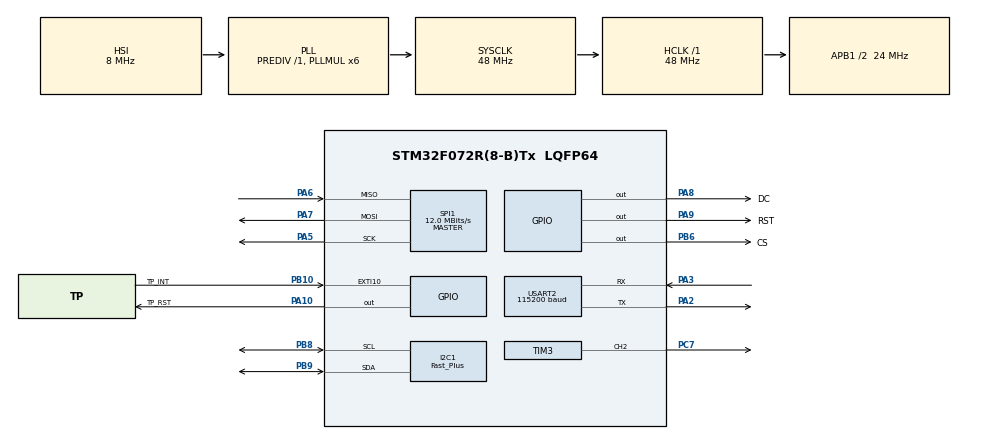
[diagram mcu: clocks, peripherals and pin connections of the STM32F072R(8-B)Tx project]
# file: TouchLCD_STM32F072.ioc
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I2C1.AddressingMode=I2C_ADDRESSINGMODE_7BIT
I2C1.DualAddressMode=I2C_DUALADDRESS_DISABLE
I2C1.GeneralCallMode=I2C_GENERALCALL_DISABLE
I2C1.I2C_Speed_Mode=I2C_Fast_Plus
I2C1.NoStretchMode=I2C_NOSTRETCH_DISABLE
I2C1.OwnAddress=0
I2C1.Timing=0x00000001
Mcu.Family=STM32F0
Mcu.Name=STM32F072R(8-B)Tx
Mcu.Package=LQFP64
NVIC.EXTI4_15_IRQn=true\:0\:0\:false\:false\:true\:true\:true\:true
PA10.GPIO_Label=TP_RST
PA10.Signal=GPIO_Output
PA13.Mode=Serial_Wire
PA13.Signal=SYS_SWDIO
PA14.Mode=Serial_Wire
PA14.Signal=SYS_SWCLK
PA2.Mode=Asynchronous
PA2.Signal=USART2_TX
PA3.Mode=Asynchronous
PA3.Signal=USART2_RX
PA5.Mode=Full_Duplex_Master
PA5.Signal=SPI1_SCK
PA6.Mode=Full_Duplex_Master
PA6.Signal=SPI1_MISO
PA7.Mode=Full_Duplex_Master
PA7.Signal=SPI1_MOSI
PA8.GPIO_Label=DC
PA8.PinState=GPIO_PIN_SET
PA8.Signal=GPIO_Output
PA9.GPIO_Label=RST
PA9.PinState=GPIO_PIN_SET
PA9.Signal=GPIO_Output
PB10.GPIO_Label=TP_INT
PB10.Signal=GPXTI10
PB6.GPIO_Label=CS
PB6.PinState=GPIO_PIN_SET
PB6.Signal=GPIO_Output
PB8.Mode=I2C
PB8.Signal=I2C1_SCL
PB9.Mode=I2C
PB9.Signal=I2C1_SDA
PC7.Signal=S_TIM3_CH2
PF0-OSC_IN.Mode=HSE-External-Oscillator
PF0-OSC_IN.Signal=RCC_OSC_IN
PF1-OSC_OUT.Mode=HSE-External-Oscillator
PF1-OSC_OUT.Signal=RCC_OSC_OUT
ProjectManager.HeapSize=0x200
ProjectManager.StackSize=0x400
ProjectManager.TargetToolchain=STM32CubeIDE
RCC.AHBFreq_Value=48000000
RCC.APB1CLKDivider=RCC_HCLK_DIV2
RCC.APB1Freq_Value=24000000
RCC.APB1TimFreq_Value=48000000
RCC.HCLKFreq_Value=48000000
RCC.PLLMUL=RCC_PLL_MUL6
RCC.PWREXT_OverDrive=PWREXT_OverDrive_ACTIVATED
RCC.PWR_Regulator_Voltage_Scale=PWR_REGULATOR_VOLTAGE_SCALE1
RCC.RCC_TIM_PRescaler_Selection=RCC_TIMPRES_DESACTIVATED
RCC.SYSCLKFreq_VALUE=48000000
RCC.SYSCLKSource=RCC_SYSCLKSOURCE_PLLCLK
SH.S_TIM3_CH2.0=TIM3_CH2,PWM Generation2 CH2
SPI1.BaudRatePrescaler=SPI_BAUDRATEPRESCALER_2
SPI1.CLKPhase=SPI_PHASE_1EDGE
SPI1.CLKPolarity=SPI_POLARITY_LOW
SPI1.CRCCalculation=SPI_CRCCALCULATION_DISABLE
SPI1.CalculateBaudRate=12.0 MBits/s
SPI1.DataSize=SPI_DATASIZE_8BIT
SPI1.Direction=SPI_DIRECTION_2LINES
SPI1.FirstBit=SPI_FIRSTBIT_MSB
SPI1.Mode=SPI_MODE_MASTER
SPI1.NSS=SPI_NSS_SOFT
SPI1.TIMode=SPI_TIMODE_DISABLE
SPI1.VirtualType=VM_MASTER
TIM3.AutoReloadPreload=TIM_AUTORELOAD_PRELOAD_ENABLE
TIM3.Channel-PWM\ Generation2\ CH2=TIM_CHANNEL_2
TIM3.ClockDivision=TIM_CLOCKDIVISION_DIV1
TIM3.CounterMode=TIM_COUNTERMODE_UP
TIM3.OC2Preload_PWM=ENABLE
TIM3.OCFastMode_PWM-PWM\ Generation2\ CH2=TIM_OCFAST_DISABLE
TIM3.OCMode_PWM-PWM\ Generation2\ CH2=TIM_OCMODE_PWM1
TIM3.OCPolarity_2=TIM_OCPOLARITY_HIGH
TIM3.Period=1000-1
TIM3.Prescaler=300-1
TIM3.Pulse-PWM\ Generation2\ CH2=0
TIM3.TIM_MasterOutputTrigger=TIM_TRGO_RESET
TIM3.TIM_MasterSlaveMode=TIM_MASTERSLAVEMODE_DISABLE
USART2.BaudRate=115200
USART2.Mode=MODE_TX_RX
USART2.Parity=PARITY_NONE
USART2.StopBits=STOPBITS_1
USART2.VirtualMode-Asynchronous=VM_ASYNC
USART2.WordLength=WORDLENGTH_8B
board=custom

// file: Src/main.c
/* USER CODE BEGIN Header */
/**
 ******************************************************************************
 * @file           : main.c
 * @brief          : Main program body
 ******************************************************************************
 * @attention
 *
 * Copyright (c) 2024 STMicroelectronics.
 * All rights reserved.
 *
 * This software is licensed under terms that can be found in the LICENSE file
 * in the root directory of this software component.
 * If no LICENSE file comes with this software, it is provided AS-IS.
 *
 ******************************************************************************
 */
/* USER CODE END Header */
#include "main.h"
#include "i2c.h"
#include "spi.h"
#include "tim.h"
#include "usart.h"
#include "gpio.h"

/* USER CODE BEGIN Includes */
#include "GUI_Paint.h"
#include "fonts.h"
#include "image.h"
#include "LCD_Test.h"

#include "transport.h"
#include "io_handling.h"
/* USER CODE END Includes */

void SystemClock_Config(void);

int main(void)
{
  /* USER CODE BEGIN 1 */
  io_handling_register_handler(transport_uart);
  /* USER CODE END 1 */

  /* MCU Configuration--------------------------------------------------------*/

  /* Reset of all peripherals, Initializes the Flash interface and the Systick. */
  HAL_Init();

  /* Configure the system clock */
  SystemClock_Config();

  /* Initialize all configured peripherals */
  MX_GPIO_Init();
  MX_SPI1_Init();
  MX_TIM3_Init();
  MX_USART2_UART_Init();
  MX_I2C1_Init();
  /* USER CODE BEGIN 2 */
  LCD_1in28_test();
  /* USER CODE END 2 */

  /* Infinite loop */
  while (1)
  {

  }
}

void SystemClock_Config(void)
{
  RCC_OscInitTypeDef RCC_OscInitStruct = {0};
  RCC_ClkInitTypeDef RCC_ClkInitStruct = {0};
  RCC_PeriphCLKInitTypeDef PeriphClkInit = {0};

  /** Initializes the RCC Oscillators according to the specified parameters
  * in the RCC_OscInitTypeDef structure.
  */
  RCC_OscInitStruct.OscillatorType = RCC_OSCILLATORTYPE_HSI;
  RCC_OscInitStruct.HSIState = RCC_HSI_ON;
  RCC_OscInitStruct.HSICalibrationValue = RCC_HSICALIBRATION_DEFAULT;
  RCC_OscInitStruct.PLL.PLLState = RCC_PLL_ON;
  RCC_OscInitStruct.PLL.PLLSource = RCC_PLLSOURCE_HSI;
  RCC_OscInitStruct.PLL.PLLMUL = RCC_PLL_MUL6;
  RCC_OscInitStruct.PLL.PREDIV = RCC_PREDIV_DIV1;
  if (HAL_RCC_OscConfig(&RCC_OscInitStruct) != HAL_OK)
  {
    Error_Handler();
  }

  /** Initializes the CPU, AHB and APB buses clocks
  */
  RCC_ClkInitStruct.ClockType = RCC_CLOCKTYPE_HCLK|RCC_CLOCKTYPE_SYSCLK
                              |RCC_CLOCKTYPE_PCLK1;
  RCC_ClkInitStruct.SYSCLKSource = RCC_SYSCLKSOURCE_PLLCLK;
  RCC_ClkInitStruct.AHBCLKDivider = RCC_SYSCLK_DIV1;
  RCC_ClkInitStruct.APB1CLKDivider = RCC_HCLK_DIV2;

  if (HAL_RCC_ClockConfig(&RCC_ClkInitStruct, FLASH_LATENCY_1) != HAL_OK)
  {
    Error_Handler();
  }
  PeriphClkInit.PeriphClockSelection = RCC_PERIPHCLK_USART2|RCC_PERIPHCLK_I2C1;
  PeriphClkInit.Usart2ClockSelection = RCC_USART2CLKSOURCE_PCLK1;
  PeriphClkInit.I2c1ClockSelection = RCC_I2C1CLKSOURCE_HSI;
  if (HAL_RCCEx_PeriphCLKConfig(&PeriphClkInit) != HAL_OK)
  {
    Error_Handler();
  }
}

void Error_Handler(void)
{
  __disable_irq();
  while (1)
  {
  }
}
